VERSION ""

NS_ :

BS_:

BU_: GWM VCU Tester

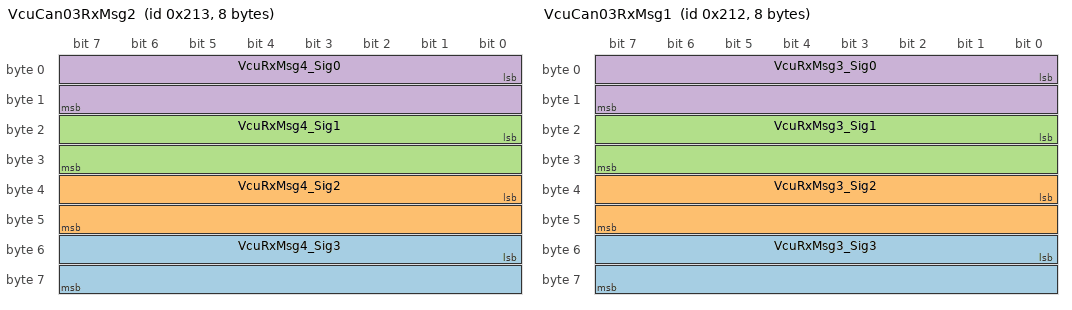
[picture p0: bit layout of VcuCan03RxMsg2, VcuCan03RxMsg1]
BO_ 531 VcuCan03RxMsg2: 8 GWM
 SG_ VcuRxMsg4_Sig3 : 48|16@1- (1,0) [0|0] ""  VCU
 SG_ VcuRxMsg4_Sig2 : 32|16@1- (1,0) [0|0] ""  VCU
 SG_ VcuRxMsg4_Sig1 : 16|16@1- (1,0) [0|0] ""  VCU
 SG_ VcuRxMsg4_Sig0 : 0|16@1- (1,0) [0|0] ""  VCU

BO_ 530 VcuCan03RxMsg1: 8 GWM
 SG_ VcuRxMsg3_Sig3 : 48|16@1- (1,0) [0|0] ""  VCU
 SG_ VcuRxMsg3_Sig2 : 32|16@1- (1,0) [0|0] ""  VCU
 SG_ VcuRxMsg3_Sig1 : 16|16@1- (1,0) [0|0] ""  VCU
 SG_ VcuRxMsg3_Sig0 : 0|16@1- (1,0) [0|0] ""  VCU

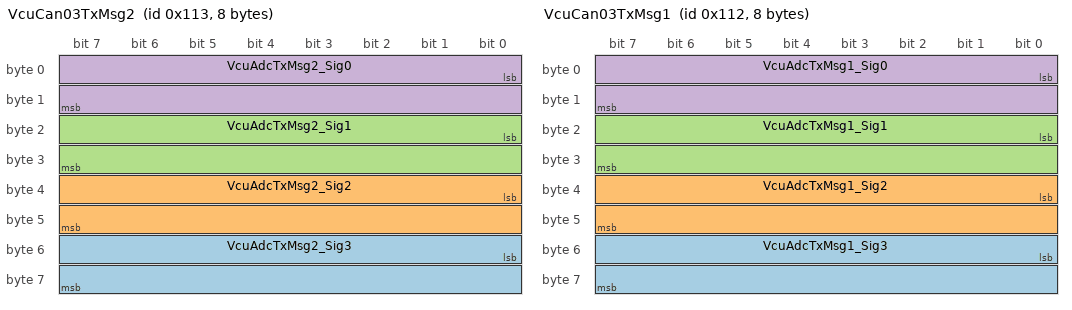
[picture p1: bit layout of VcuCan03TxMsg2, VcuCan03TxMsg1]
BO_ 275 VcuCan03TxMsg2: 8 VCU
 SG_ VcuAdcTxMsg2_Sig3 : 48|16@1- (1,0) [0|0] ""  GWM
 SG_ VcuAdcTxMsg2_Sig2 : 32|16@1- (1,0) [0|0] ""  GWM
 SG_ VcuAdcTxMsg2_Sig1 : 16|16@1- (1,0) [0|0] ""  GWM
 SG_ VcuAdcTxMsg2_Sig0 : 0|16@1- (1,0) [0|0] ""  GWM

BO_ 274 VcuCan03TxMsg1: 8 VCU
 SG_ VcuAdcTxMsg1_Sig3 : 48|16@1- (1,0) [0|0] ""  GWM
 SG_ VcuAdcTxMsg1_Sig2 : 32|16@1- (1,0) [0|0] ""  GWM
 SG_ VcuAdcTxMsg1_Sig1 : 16|16@1- (1,0) [0|0] ""  GWM
 SG_ VcuAdcTxMsg1_Sig0 : 0|16@1- (1,0) [0|0] ""  GWM

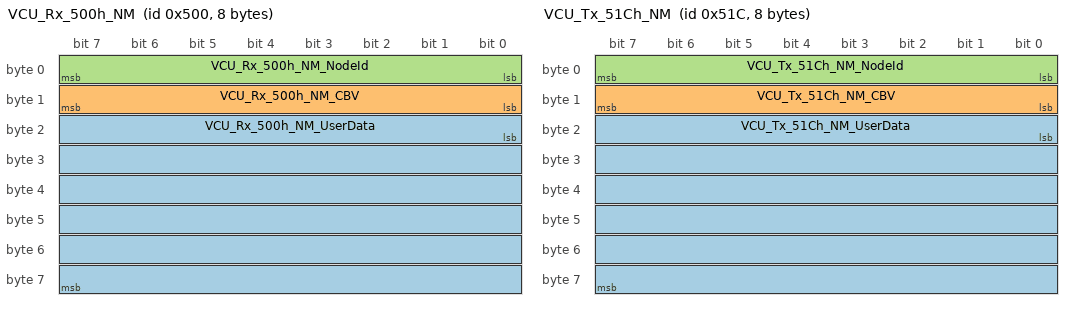
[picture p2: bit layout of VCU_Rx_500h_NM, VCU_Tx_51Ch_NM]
BO_ 1280 VCU_Rx_500h_NM: 8 GWM
 SG_ VCU_Rx_500h_NM_UserData : 16|48@1+ (1,0) [0|0] ""  VCU
 SG_ VCU_Rx_500h_NM_CBV : 8|8@1+ (1,0) [0|0] ""  VCU
 SG_ VCU_Rx_500h_NM_NodeId : 0|8@1+ (1,0) [0|0] ""  VCU

BO_ 1308 VCU_Tx_51Ch_NM: 8 VCU
 SG_ VCU_Tx_51Ch_NM_UserData : 16|48@1+ (1,0) [0|0] ""  GWM
 SG_ VCU_Tx_51Ch_NM_CBV : 8|8@1+ (1,0) [0|0] ""  GWM
 SG_ VCU_Tx_51Ch_NM_NodeId : 0|8@1+ (1,0) [0|0] ""  GWM

BA_DEF_ BO_  "VFrameFormat" ENUM  "StandardCAN","ExtendedCAN","reserved","reserved","reserved","reserved","reserved","reserved","reserved","reserved","reserved","reserved","reserved","reserved","StandardCAN_FD","ExtendedCAN_FD";
BA_DEF_ BO_  "GenMsgCycleTime" INT 0 0;
BA_DEF_ BO_  "GenMsgSendType" ENUM  "Cyclic","NotUsed","NotUsed","NotUsed","NotUsed","NotUsed","NotUsed","IfActive","NoMsgSendType","NotUsed";
BA_DEF_ SG_  "GenSigSendType" ENUM  "Cyclic","OnWrite","OnWriteWithRepetition","OnChange","OnChangeWithRepetition","IfActive","IfActiveWithRepetition","NoSigSendType","NotUsed","NotUsed","NotUsed","NotUsed","NotUsed";
BA_DEF_  "Baudrate" INT 0 1000000;
BA_DEF_  "BusType" STRING ;
BA_DEF_  "NmType" STRING ;
BA_DEF_  "Manufacturer" STRING ;
BA_DEF_ BU_  "NodeLayerModules" STRING ;
BA_DEF_ BO_  "NmMessage" ENUM  "no","yes";
BA_DEF_  "NmAsrWaitBusSleepTime" INT 0 65535;
BA_DEF_  "NmAsrTimeoutTime" INT 1 65535;
BA_DEF_  "NmAsrRepeatMessageTime" INT 0 65535;
BA_DEF_ BU_  "NmAsrNodeIdentifier" HEX 0 255;
BA_DEF_ BU_  "NmAsrNode" ENUM  "no","yes";
BA_DEF_  "NmAsrMessageCount" INT 1 256;
BA_DEF_ BO_  "NmAsrMessage" ENUM  "no","yes";
BA_DEF_ BU_  "NmAsrCanMsgReducedTime" INT 1 65535;
BA_DEF_  "NmAsrCanMsgCycleTime" INT 1 65535;
BA_DEF_  "NmAsrBaseAddress" HEX 0 2047;
BA_DEF_ BU_  "ILUsed" ENUM  "no","yes";
BA_DEF_ BO_  "GenMsgILSupport" ENUM  "no","yes";
BA_DEF_  "DBName" STRING ;
BA_DEF_DEF_  "VFrameFormat" "ExtendedCAN_FD";
BA_DEF_DEF_  "GenMsgCycleTime" 0;
BA_DEF_DEF_  "GenMsgSendType" "Cyclic";
BA_DEF_DEF_  "GenSigSendType" "Cyclic";
BA_DEF_DEF_  "Baudrate" 500000;
BA_DEF_DEF_  "BusType" "";
BA_DEF_DEF_  "NmType" "";
BA_DEF_DEF_  "Manufacturer" "Vector";
BA_DEF_DEF_  "NodeLayerModules" " ";
BA_DEF_DEF_  "NmMessage" "no";
BA_DEF_DEF_  "NmAsrWaitBusSleepTime" 2000;
BA_DEF_DEF_  "NmAsrTimeoutTime" 2000;
BA_DEF_DEF_  "NmAsrRepeatMessageTime" 1500;
BA_DEF_DEF_  "NmAsrNodeIdentifier" 28;
BA_DEF_DEF_  "NmAsrNode" "yes";
BA_DEF_DEF_  "NmAsrMessageCount" 128;
BA_DEF_DEF_  "NmAsrMessage" "no";
BA_DEF_DEF_  "NmAsrCanMsgReducedTime" 320;
BA_DEF_DEF_  "NmAsrCanMsgCycleTime" 500;
BA_DEF_DEF_  "NmAsrBaseAddress" 1024;
BA_DEF_DEF_  "ILUsed" "yes";
BA_DEF_DEF_  "GenMsgILSupport" "yes";
BA_DEF_DEF_  "DBName" "";
BA_ "BusType" "CAN";
BA_ "NmType" "NmAsr";
BA_ "DBName" "TC37X_VCU_CAN03";
BA_ "VFrameFormat" BO_ 531 0;
BA_ "GenMsgCycleTime" BO_ 531 500;
BA_ "VFrameFormat" BO_ 530 0;
BA_ "GenMsgCycleTime" BO_ 530 500;
BA_ "VFrameFormat" BO_ 275 0;
BA_ "GenMsgCycleTime" BO_ 275 500;
BA_ "VFrameFormat" BO_ 274 0;
BA_ "GenMsgCycleTime" BO_ 274 500;
BA_ "VFrameFormat" BO_ 1280 0;
BA_ "GenMsgCycleTime" BO_ 1280 500;
BA_ "NmAsrMessage" BO_ 1280 1;
BA_ "NmMessage" BO_ 1280 1;
BA_ "VFrameFormat" BO_ 1308 0;
BA_ "GenMsgCycleTime" BO_ 1308 500;
BA_ "NmAsrMessage" BO_ 1308 1;
BA_ "NmMessage" BO_ 1308 1;
